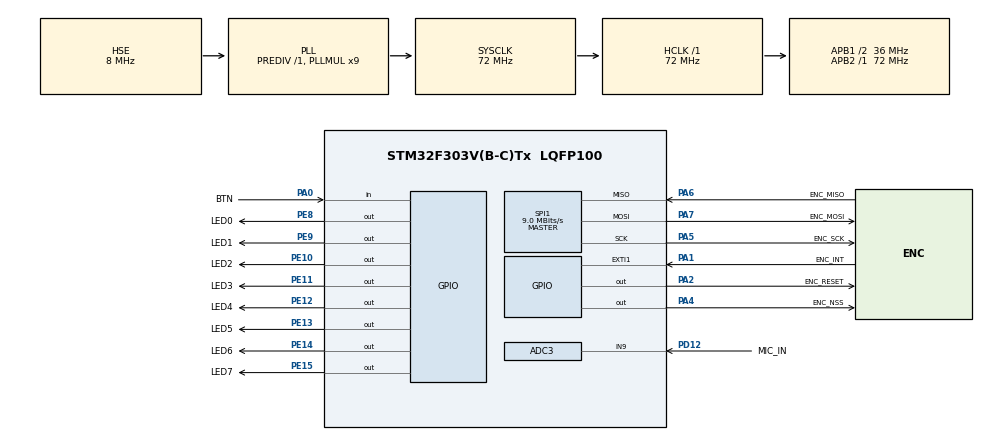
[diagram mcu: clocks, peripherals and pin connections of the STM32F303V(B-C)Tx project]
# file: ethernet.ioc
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ADC3.Channel-2\#ChannelRegularConversion=ADC_CHANNEL_9
ADC3.ClockPrescaler=ADC_CLOCK_SYNC_PCLK_DIV1
ADC3.DMAContinuousRequests=ENABLE
ADC3.ExternalTrigConv=ADC_EXTERNALTRIGCONV_T3_TRGO
ADC3.NbrOfConversionFlag=1
ADC3.Offset-2\#ChannelRegularConversion=0
ADC3.OffsetNumber-2\#ChannelRegularConversion=ADC_OFFSET_NONE
ADC3.Rank-2\#ChannelRegularConversion=1
ADC3.SamplingTime-2\#ChannelRegularConversion=ADC_SAMPLETIME_1CYCLE_5
ADC3.SamplingTimeOPAMP-2\#ChannelRegularConversion=ADC_SAMPLETIME_61CYCLES_5
ADC3.master=1
Dma.ADC3.2.Direction=DMA_PERIPH_TO_MEMORY
Dma.ADC3.2.Instance=DMA2_Channel5
Dma.ADC3.2.MemDataAlignment=DMA_MDATAALIGN_HALFWORD
Dma.ADC3.2.MemInc=DMA_MINC_ENABLE
Dma.ADC3.2.Mode=DMA_CIRCULAR
Dma.ADC3.2.PeriphDataAlignment=DMA_PDATAALIGN_HALFWORD
Dma.ADC3.2.PeriphInc=DMA_PINC_DISABLE
Dma.ADC3.2.Priority=DMA_PRIORITY_MEDIUM
Dma.Request0=SPI1_RX
Dma.Request1=SPI1_TX
Dma.Request2=ADC3
Dma.SPI1_RX.0.Direction=DMA_PERIPH_TO_MEMORY
Dma.SPI1_RX.0.Instance=DMA1_Channel2
Dma.SPI1_RX.0.MemDataAlignment=DMA_MDATAALIGN_BYTE
Dma.SPI1_RX.0.MemInc=DMA_MINC_ENABLE
Dma.SPI1_RX.0.Mode=DMA_NORMAL
Dma.SPI1_RX.0.PeriphDataAlignment=DMA_PDATAALIGN_BYTE
Dma.SPI1_RX.0.PeriphInc=DMA_PINC_DISABLE
Dma.SPI1_RX.0.Priority=DMA_PRIORITY_MEDIUM
Dma.SPI1_TX.1.Direction=DMA_MEMORY_TO_PERIPH
Dma.SPI1_TX.1.Instance=DMA1_Channel3
Dma.SPI1_TX.1.MemDataAlignment=DMA_MDATAALIGN_BYTE
Dma.SPI1_TX.1.MemInc=DMA_MINC_ENABLE
Dma.SPI1_TX.1.Mode=DMA_NORMAL
Dma.SPI1_TX.1.PeriphDataAlignment=DMA_PDATAALIGN_BYTE
Dma.SPI1_TX.1.PeriphInc=DMA_PINC_DISABLE
Dma.SPI1_TX.1.Priority=DMA_PRIORITY_MEDIUM
FREERTOS.HEAP_NUMBER=5
FREERTOS.INCLUDE_uxTaskPriorityGet=1
FREERTOS.INCLUDE_vTaskCleanUpResources=1
FREERTOS.INCLUDE_vTaskDelete=1
FREERTOS.INCLUDE_vTaskPrioritySet=1
FREERTOS.INCLUDE_xEventGroupSetBitFromISR=1
FREERTOS.INCLUDE_xTaskGetCurrentTaskHandle=1
FREERTOS.INCLUDE_xTaskGetHandle=1
FREERTOS.Tasks01=VCP2CLITask,24,128,vcp_task,Default,NULL,Dynamic,NULL,NULL
FREERTOS.configCHECK_FOR_STACK_OVERFLOW=0
FREERTOS.configGENERATE_RUN_TIME_STATS=1
FREERTOS.configTIMER_TASK_STACK_DEPTH=128
FREERTOS.configTOTAL_HEAP_SIZE=15360
FREERTOS.configUSE_IDLE_HOOK=1
FREERTOS.configUSE_MALLOC_FAILED_HOOK=1
FREERTOS.configUSE_NEWLIB_REENTRANT=1
FREERTOS.configUSE_STATS_FORMATTING_FUNCTIONS=1
Mcu.Family=STM32F3
Mcu.Name=STM32F303V(B-C)Tx
Mcu.Package=LQFP100
NVIC.DMA1_Channel2_IRQn=true\:5\:0\:false\:false\:true\:true\:false\:true
NVIC.DMA1_Channel3_IRQn=true\:5\:0\:false\:false\:true\:true\:false\:true
NVIC.DMA2_Channel5_IRQn=true\:5\:0\:false\:false\:true\:true\:false\:true
NVIC.EXTI1_IRQn=true\:5\:0\:false\:false\:true\:true\:true\:true
NVIC.PriorityGroup=NVIC_PRIORITYGROUP_4
NVIC.TIM2_IRQn=true\:15\:0\:false\:false\:true\:false\:false\:true
NVIC.TIM4_IRQn=true\:5\:0\:false\:false\:true\:true\:true\:true
NVIC.TimeBase=TIM2_IRQn
NVIC.TimeBaseIP=TIM2
PA0.GPIO_Label=BTN
PA0.Signal=GPIO_Input
PA1.GPIO_Label=ENC_INT
PA1.GPIO_ModeDefaultEXTI=GPIO_MODE_IT_FALLING
PA1.GPIO_PuPd=GPIO_NOPULL
PA1.Signal=GPXTI1
PA2.GPIO_Label=ENC_RESET
PA2.Signal=GPIO_Output
PA4.GPIO_Label=ENC_NSS
PA4.Signal=GPIO_Output
PA5.GPIO_Label=ENC_SCK
PA5.GPIO_PuPd=GPIO_PULLDOWN
PA5.Mode=Full_Duplex_Master
PA5.Signal=SPI1_SCK
PA6.GPIO_Label=ENC_MISO
PA6.Mode=Full_Duplex_Master
PA6.Signal=SPI1_MISO
PA7.GPIO_Label=ENC_MOSI
PA7.GPIO_PuPd=GPIO_PULLDOWN
PA7.Mode=Full_Duplex_Master
PA7.Signal=SPI1_MOSI
PD12.GPIO_Label=MIC_IN
PD12.Signal=ADCx_IN9P
PE10.GPIO_Label=LED2
PE10.Signal=GPIO_Output
PE11.GPIO_Label=LED3
PE11.Signal=GPIO_Output
PE12.GPIO_Label=LED4
PE12.Signal=GPIO_Output
PE13.GPIO_Label=LED5
PE13.Signal=GPIO_Output
PE14.GPIO_Label=LED6
PE14.Signal=GPIO_Output
PE15.GPIO_Label=LED7
PE15.Signal=GPIO_Output
PE8.GPIO_Label=LED0
PE8.Signal=GPIO_Output
PE9.GPIO_Label=LED1
PE9.Signal=GPIO_Output
PF0-OSC_IN.Mode=HSE-External-Oscillator
PF0-OSC_IN.Signal=RCC_OSC_IN
PF1-OSC_OUT.Mode=HSE-External-Oscillator
PF1-OSC_OUT.Signal=RCC_OSC_OUT
ProjectManager.HeapSize=0x0800
ProjectManager.StackSize=0x1000
ProjectManager.TargetToolchain=STM32CubeIDE
RCC.AHBFreq_Value=72000000
RCC.APB1CLKDivider=RCC_HCLK_DIV2
RCC.APB1Freq_Value=36000000
RCC.APB1TimFreq_Value=72000000
RCC.APB2Freq_Value=72000000
RCC.APB2TimFreq_Value=72000000
RCC.CortexFreq_Value=72000000
RCC.HCLKFreq_Value=72000000
RCC.HSE_VALUE=8000000
RCC.HSI_VALUE=8000000
RCC.LSE_VALUE=32768
RCC.PLLMUL=RCC_PLL_MUL9
RCC.PLLSourceVirtual=RCC_PLLSOURCE_HSE
RCC.PRESCALERUSB=RCC_USBCLKSOURCE_PLL_DIV1_5
RCC.SYSCLKFreq_VALUE=72000000
RCC.SYSCLKSourceVirtual=RCC_SYSCLKSOURCE_PLLCLK
RCC.USBFreq_Value=48000000
SH.ADCx_IN9P.0=ADC3_IN9,IN9-Single-Ended
SPI1.BaudRatePrescaler=SPI_BAUDRATEPRESCALER_8
SPI1.CLKPhase=SPI_PHASE_1EDGE
SPI1.CalculateBaudRate=9.0 MBits/s
SPI1.DataSize=SPI_DATASIZE_8BIT
SPI1.Direction=SPI_DIRECTION_2LINES
SPI1.Mode=SPI_MODE_MASTER
SPI1.TIMode=SPI_TIMODE_DISABLE
SPI1.VirtualType=VM_MASTER
STMicroelectronics.X-CUBE-ALGOBUILD.1.2.1.LibraryCcDSPOoLibraryJjDSPOoLibrary=true
TIM1.AutoReloadPreload=TIM_AUTORELOAD_PRELOAD_ENABLE
TIM1.Period=8999
TIM1.Prescaler=7
TIM3.AutoReloadPreload=TIM_AUTORELOAD_PRELOAD_ENABLE
TIM3.Period=1499
TIM3.TIM_MasterOutputTrigger=TIM_TRGO_UPDATE
TIM4.AutoReloadPreload=TIM_AUTORELOAD_PRELOAD_ENABLE
TIM4.Period=719
TIM4.TIM_MasterOutputTrigger=TIM_TRGO_RESET
VP_FREERTOS_VS_CMSIS_V2.Mode=CMSIS_V2
VP_STMicroelectronics.X-CUBE-ALGOBUILD_VS_DSPOoLibraryJjLibrary_1.2.1_1.2.1.Mode=DSPOoLibraryJjLibrary
VP_SYS_VS_tim2.Mode=TIM2
VP_TIM1_VS_ClockSourceINT.Mode=Internal
VP_TIM3_VS_ClockSourceINT.Mode=Internal
VP_TIM4_VS_ClockSourceINT.Mode=Internal
board=custom

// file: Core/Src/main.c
/* USER CODE BEGIN Header */
/**
  ******************************************************************************
  * @file           : main.c
  * @brief          : Main program body
  ******************************************************************************
  * @attention
  *
  * Copyright (c) 2021 STMicroelectronics.
  * All rights reserved.
  *
  * This software is licensed under terms that can be found in the LICENSE file
  * in the root directory of this software component.
  * If no LICENSE file comes with this software, it is provided AS-IS.
  *
  ******************************************************************************
  */
/* USER CODE END Header */
#include "main.h"
#include "cmsis_os.h"

/* USER CODE BEGIN Includes */
//#include "usbd_cdc_if.h"
/* USER CODE END Includes */

ADC_HandleTypeDef hadc3;
DMA_HandleTypeDef hdma_adc3;

SPI_HandleTypeDef hspi1;
DMA_HandleTypeDef hdma_spi1_rx;
DMA_HandleTypeDef hdma_spi1_tx;

TIM_HandleTypeDef htim1;
TIM_HandleTypeDef htim3;
TIM_HandleTypeDef htim4;

/* Definitions for VCP2CLITask */
osThreadId_t VCP2CLITaskHandle;
const osThreadAttr_t VCP2CLITask_attributes = {
  .name = "VCP2CLITask",
  .stack_size = 128 * 4,
  .priority = (osPriority_t) osPriorityNormal,
};

void SystemClock_Config(void);
static void MX_GPIO_Init(void);
static void MX_SPI1_Init(void);
static void MX_TIM1_Init(void);
static void MX_DMA_Init(void);
static void MX_TIM4_Init(void);
static void MX_ADC3_Init(void);
static void MX_TIM3_Init(void);
void vcp_task(void *argument);

/* USER CODE BEGIN 0 */
unsigned long taskruntime = 0;

void configureTimerForRunTimeStats(void){
	HAL_TIM_Base_Start_IT(&htim4);
}
unsigned long getRunTimeCounterValue(void){
	return taskruntime;
}

/* USER CODE END 0 */

int main(void)
{

  /* MCU Configuration--------------------------------------------------------*/

  /* Reset of all peripherals, Initializes the Flash interface and the Systick. */
  HAL_Init();

  /* Configure the system clock */
  SystemClock_Config();

  /* Initialize all configured peripherals */
  MX_GPIO_Init();
  MX_SPI1_Init();
  MX_TIM1_Init();
  MX_DMA_Init();
  MX_TIM4_Init();
  MX_ADC3_Init();
  MX_TIM3_Init();

  /* Init scheduler */
  osKernelInitialize();

  /* Create the thread(s) */
  /* creation of VCP2CLITask */
//  VCP2CLITaskHandle = osThreadNew(vcp_task, NULL, &VCP2CLITask_attributes);

  /* USER CODE BEGIN RTOS_THREADS */
  /* add threads, ... */
  adc_fft_start();
  FreeRTOS_ENC28J60Init();

  /* USER CODE END RTOS_THREADS */

  /* Start scheduler */
  osKernelStart();

  /* We should never get here as control is now taken by the scheduler */
  /* Infinite loop */
  while (1)
  {

  }
}

void SystemClock_Config(void)
{
  RCC_OscInitTypeDef RCC_OscInitStruct = {0};
  RCC_ClkInitTypeDef RCC_ClkInitStruct = {0};
  RCC_PeriphCLKInitTypeDef PeriphClkInit = {0};

  /** Initializes the RCC Oscillators according to the specified parameters
  * in the RCC_OscInitTypeDef structure.
  */
  RCC_OscInitStruct.OscillatorType = RCC_OSCILLATORTYPE_HSE;
  RCC_OscInitStruct.HSEState = RCC_HSE_ON;
  RCC_OscInitStruct.HSEPredivValue = RCC_HSE_PREDIV_DIV1;
  RCC_OscInitStruct.HSIState = RCC_HSI_ON;
  RCC_OscInitStruct.PLL.PLLState = RCC_PLL_ON;
  RCC_OscInitStruct.PLL.PLLSource = RCC_PLLSOURCE_HSE;
  RCC_OscInitStruct.PLL.PLLMUL = RCC_PLL_MUL9;
  if (HAL_RCC_OscConfig(&RCC_OscInitStruct) != HAL_OK)
  {
    Error_Handler();
  }
  /** Initializes the CPU, AHB and APB buses clocks
  */
  RCC_ClkInitStruct.ClockType = RCC_CLOCKTYPE_HCLK|RCC_CLOCKTYPE_SYSCLK
                              |RCC_CLOCKTYPE_PCLK1|RCC_CLOCKTYPE_PCLK2;
  RCC_ClkInitStruct.SYSCLKSource = RCC_SYSCLKSOURCE_PLLCLK;
  RCC_ClkInitStruct.AHBCLKDivider = RCC_SYSCLK_DIV1;
  RCC_ClkInitStruct.APB1CLKDivider = RCC_HCLK_DIV2;
  RCC_ClkInitStruct.APB2CLKDivider = RCC_HCLK_DIV1;

  if (HAL_RCC_ClockConfig(&RCC_ClkInitStruct, FLASH_LATENCY_2) != HAL_OK)
  {
    Error_Handler();
  }
  PeriphClkInit.PeriphClockSelection = RCC_PERIPHCLK_TIM1;
  PeriphClkInit.Tim1ClockSelection = RCC_TIM1CLK_HCLK;
  if (HAL_RCCEx_PeriphCLKConfig(&PeriphClkInit) != HAL_OK)
  {
    Error_Handler();
  }
}

static void MX_ADC3_Init(void)
{

  ADC_MultiModeTypeDef multimode = {0};
  ADC_ChannelConfTypeDef sConfig = {0};

  /** Common config
  */
  hadc3.Instance = ADC3;
  hadc3.Init.ClockPrescaler = ADC_CLOCK_SYNC_PCLK_DIV1;
  hadc3.Init.Resolution = ADC_RESOLUTION_12B;
  hadc3.Init.ScanConvMode = ADC_SCAN_DISABLE;
  hadc3.Init.ContinuousConvMode = DISABLE;
  hadc3.Init.DiscontinuousConvMode = DISABLE;
  hadc3.Init.ExternalTrigConvEdge = ADC_EXTERNALTRIGCONVEDGE_RISING;
  hadc3.Init.ExternalTrigConv = ADC_EXTERNALTRIGCONV_T3_TRGO;
  hadc3.Init.DataAlign = ADC_DATAALIGN_RIGHT;
  hadc3.Init.NbrOfConversion = 1;
  hadc3.Init.DMAContinuousRequests = ENABLE;
  hadc3.Init.EOCSelection = ADC_EOC_SINGLE_CONV;
  hadc3.Init.LowPowerAutoWait = DISABLE;
  hadc3.Init.Overrun = ADC_OVR_DATA_OVERWRITTEN;
  if (HAL_ADC_Init(&hadc3) != HAL_OK)
  {
    Error_Handler();
  }
  /** Configure the ADC multi-mode
  */
  multimode.Mode = ADC_MODE_INDEPENDENT;
  if (HAL_ADCEx_MultiModeConfigChannel(&hadc3, &multimode) != HAL_OK)
  {
    Error_Handler();
  }
  /** Configure Regular Channel
  */
  sConfig.Channel = ADC_CHANNEL_9;
  sConfig.Rank = ADC_REGULAR_RANK_1;
  sConfig.SingleDiff = ADC_SINGLE_ENDED;
  sConfig.SamplingTime = ADC_SAMPLETIME_1CYCLE_5;
  sConfig.OffsetNumber = ADC_OFFSET_NONE;
  sConfig.Offset = 0;
  if (HAL_ADC_ConfigChannel(&hadc3, &sConfig) != HAL_OK)
  {
    Error_Handler();
  }

}

static void MX_SPI1_Init(void)
{

  /* SPI1 parameter configuration*/
  hspi1.Instance = SPI1;
  hspi1.Init.Mode = SPI_MODE_MASTER;
  hspi1.Init.Direction = SPI_DIRECTION_2LINES;
  hspi1.Init.DataSize = SPI_DATASIZE_8BIT;
  hspi1.Init.CLKPolarity = SPI_POLARITY_LOW;
  hspi1.Init.CLKPhase = SPI_PHASE_1EDGE;
  hspi1.Init.NSS = SPI_NSS_SOFT;
  hspi1.Init.BaudRatePrescaler = SPI_BAUDRATEPRESCALER_8;
  hspi1.Init.FirstBit = SPI_FIRSTBIT_MSB;
  hspi1.Init.TIMode = SPI_TIMODE_DISABLE;
  hspi1.Init.CRCCalculation = SPI_CRCCALCULATION_DISABLE;
  hspi1.Init.CRCPolynomial = 7;
  hspi1.Init.CRCLength = SPI_CRC_LENGTH_DATASIZE;
  hspi1.Init.NSSPMode = SPI_NSS_PULSE_ENABLE;
  if (HAL_SPI_Init(&hspi1) != HAL_OK)
  {
    Error_Handler();
  }

}

static void MX_TIM1_Init(void)
{

  TIM_ClockConfigTypeDef sClockSourceConfig = {0};
  TIM_MasterConfigTypeDef sMasterConfig = {0};

  htim1.Instance = TIM1;
  htim1.Init.Prescaler = 7;
  htim1.Init.CounterMode = TIM_COUNTERMODE_UP;
  htim1.Init.Period = 8999;
  htim1.Init.ClockDivision = TIM_CLOCKDIVISION_DIV1;
  htim1.Init.RepetitionCounter = 0;
  htim1.Init.AutoReloadPreload = TIM_AUTORELOAD_PRELOAD_ENABLE;
  if (HAL_TIM_Base_Init(&htim1) != HAL_OK)
  {
    Error_Handler();
  }
  sClockSourceConfig.ClockSource = TIM_CLOCKSOURCE_INTERNAL;
  if (HAL_TIM_ConfigClockSource(&htim1, &sClockSourceConfig) != HAL_OK)
  {
    Error_Handler();
  }
  sMasterConfig.MasterOutputTrigger = TIM_TRGO_RESET;
  sMasterConfig.MasterOutputTrigger2 = TIM_TRGO2_RESET;
  sMasterConfig.MasterSlaveMode = TIM_MASTERSLAVEMODE_DISABLE;
  if (HAL_TIMEx_MasterConfigSynchronization(&htim1, &sMasterConfig) != HAL_OK)
  {
    Error_Handler();
  }

}

static void MX_TIM3_Init(void)
{

  TIM_ClockConfigTypeDef sClockSourceConfig = {0};
  TIM_MasterConfigTypeDef sMasterConfig = {0};

  htim3.Instance = TIM3;
  htim3.Init.Prescaler = 0;
  htim3.Init.CounterMode = TIM_COUNTERMODE_UP;
  htim3.Init.Period = 1499;
  htim3.Init.ClockDivision = TIM_CLOCKDIVISION_DIV1;
  htim3.Init.AutoReloadPreload = TIM_AUTORELOAD_PRELOAD_ENABLE;
  if (HAL_TIM_Base_Init(&htim3) != HAL_OK)
  {
    Error_Handler();
  }
  sClockSourceConfig.ClockSource = TIM_CLOCKSOURCE_INTERNAL;
  if (HAL_TIM_ConfigClockSource(&htim3, &sClockSourceConfig) != HAL_OK)
  {
    Error_Handler();
  }
  sMasterConfig.MasterOutputTrigger = TIM_TRGO_UPDATE;
  sMasterConfig.MasterSlaveMode = TIM_MASTERSLAVEMODE_DISABLE;
  if (HAL_TIMEx_MasterConfigSynchronization(&htim3, &sMasterConfig) != HAL_OK)
  {
    Error_Handler();
  }

}

static void MX_TIM4_Init(void)
{

  TIM_ClockConfigTypeDef sClockSourceConfig = {0};
  TIM_MasterConfigTypeDef sMasterConfig = {0};

  htim4.Instance = TIM4;
  htim4.Init.Prescaler = 0;
  htim4.Init.CounterMode = TIM_COUNTERMODE_UP;
  htim4.Init.Period = 719;
  htim4.Init.ClockDivision = TIM_CLOCKDIVISION_DIV1;
  htim4.Init.AutoReloadPreload = TIM_AUTORELOAD_PRELOAD_ENABLE;
  if (HAL_TIM_Base_Init(&htim4) != HAL_OK)
  {
    Error_Handler();
  }
  sClockSourceConfig.ClockSource = TIM_CLOCKSOURCE_INTERNAL;
  if (HAL_TIM_ConfigClockSource(&htim4, &sClockSourceConfig) != HAL_OK)
  {
    Error_Handler();
  }
  sMasterConfig.MasterOutputTrigger = TIM_TRGO_RESET;
  sMasterConfig.MasterSlaveMode = TIM_MASTERSLAVEMODE_DISABLE;
  if (HAL_TIMEx_MasterConfigSynchronization(&htim4, &sMasterConfig) != HAL_OK)
  {
    Error_Handler();
  }

}

static void MX_DMA_Init(void)
{

  /* DMA controller clock enable */
  __HAL_RCC_DMA1_CLK_ENABLE();
  __HAL_RCC_DMA2_CLK_ENABLE();

  /* DMA interrupt init */
  /* DMA1_Channel2_IRQn interrupt configuration */
  HAL_NVIC_SetPriority(DMA1_Channel2_IRQn, 5, 0);
  HAL_NVIC_EnableIRQ(DMA1_Channel2_IRQn);
  /* DMA1_Channel3_IRQn interrupt configuration */
  HAL_NVIC_SetPriority(DMA1_Channel3_IRQn, 5, 0);
  HAL_NVIC_EnableIRQ(DMA1_Channel3_IRQn);
  /* DMA2_Channel5_IRQn interrupt configuration */
  HAL_NVIC_SetPriority(DMA2_Channel5_IRQn, 5, 0);
  HAL_NVIC_EnableIRQ(DMA2_Channel5_IRQn);

}

static void MX_GPIO_Init(void)
{
  GPIO_InitTypeDef GPIO_InitStruct = {0};

  /* GPIO Ports Clock Enable */
  __HAL_RCC_GPIOF_CLK_ENABLE();
  __HAL_RCC_GPIOA_CLK_ENABLE();
  __HAL_RCC_GPIOE_CLK_ENABLE();
  __HAL_RCC_GPIOD_CLK_ENABLE();

  /*Configure GPIO pin Output Level */
  HAL_GPIO_WritePin(GPIOA, ENC_RESET_Pin|ENC_NSS_Pin, GPIO_PIN_RESET);

  /*Configure GPIO pin Output Level */
  HAL_GPIO_WritePin(GPIOE, LED0_Pin|LED1_Pin|LED2_Pin|LED3_Pin
                          |LED4_Pin|LED5_Pin|LED6_Pin|LED7_Pin, GPIO_PIN_RESET);

  /*Configure GPIO pin : BTN_Pin */
  GPIO_InitStruct.Pin = BTN_Pin;
  GPIO_InitStruct.Mode = GPIO_MODE_INPUT;
  GPIO_InitStruct.Pull = GPIO_NOPULL;
  HAL_GPIO_Init(BTN_GPIO_Port, &GPIO_InitStruct);

  /*Configure GPIO pin : ENC_INT_Pin */
  GPIO_InitStruct.Pin = ENC_INT_Pin;
  GPIO_InitStruct.Mode = GPIO_MODE_IT_FALLING;
  GPIO_InitStruct.Pull = GPIO_NOPULL;
  HAL_GPIO_Init(ENC_INT_GPIO_Port, &GPIO_InitStruct);

  /*Configure GPIO pins : ENC_RESET_Pin ENC_NSS_Pin */
  GPIO_InitStruct.Pin = ENC_RESET_Pin|ENC_NSS_Pin;
  GPIO_InitStruct.Mode = GPIO_MODE_OUTPUT_PP;
  GPIO_InitStruct.Pull = GPIO_NOPULL;
  GPIO_InitStruct.Speed = GPIO_SPEED_FREQ_LOW;
  HAL_GPIO_Init(GPIOA, &GPIO_InitStruct);

  /*Configure GPIO pins : LED0_Pin LED1_Pin LED2_Pin LED3_Pin
                           LED4_Pin LED5_Pin LED6_Pin LED7_Pin */
  GPIO_InitStruct.Pin = LED0_Pin|LED1_Pin|LED2_Pin|LED3_Pin
                          |LED4_Pin|LED5_Pin|LED6_Pin|LED7_Pin;
  GPIO_InitStruct.Mode = GPIO_MODE_OUTPUT_PP;
  GPIO_InitStruct.Pull = GPIO_NOPULL;
  GPIO_InitStruct.Speed = GPIO_SPEED_FREQ_LOW;
  HAL_GPIO_Init(GPIOE, &GPIO_InitStruct);

  /* EXTI interrupt init*/
  HAL_NVIC_SetPriority(EXTI1_IRQn, 5, 0);
  HAL_NVIC_EnableIRQ(EXTI1_IRQn);

}

/* USER CODE BEGIN 4 */
//uint8_t usb_rx_flag = 0;
//extern uint8_t UserRxBufferFS[APP_RX_DATA_SIZE];
//extern uint8_t UserTxBufferFS[APP_TX_DATA_SIZE];
//char usb_rx_buffer[1400] = {0};
//char usb_tx_buffer[1400] = {0};

//uint16_t len = 0;
/* USER CODE END 4 */

void vcp_task(void *argument)
{
  /* USER CODE BEGIN 5 */
  /* Infinite loop */
  for(;;){

	 // ulTaskNotifyTake(pdFALSE, portMAX_DELAY);
	  /*
	  while(CDC_Transmit_FS(UserRxBufferFS, strlen(UserRxBufferFS) != USBD_OK)){};

	  if(UserRxBufferFS[0] != '\r'){
		  //while(CDC_Transmit_FS(UserRxBufferFS, strlen(UserRxBufferFS) != USBD_OK)){};

		  //UserRxBufferFS[strlen(UserRxBufferFS)] = 0x00;
		  strncpy(usb_rx_buffer + strlen(usb_rx_buffer), UserRxBufferFS, 2);
	  }else{
		  //while(CDC_Transmit_FS("\r\n", sizeof("\r\n") != USBD_OK)){}

		  UserTxBufferFS[0] = 0;

		  FreeRTOS_CLIProcessCommand(usb_rx_buffer, UserTxBufferFS, APP_TX_DATA_SIZE);

		  usb_rx_buffer[0] = 0;
		  while(CDC_Transmit_FS(UserTxBufferFS, strlen(UserTxBufferFS)) != USBD_OK){};
	  }
	  */
  }
  /* USER CODE END 5 */
}

void HAL_TIM_PeriodElapsedCallback(TIM_HandleTypeDef *htim)
{
  if (htim->Instance == TIM2) {
    HAL_IncTick();
  }
  /* USER CODE BEGIN Callback 1 */
  else if(htim->Instance == TIM4){
	  taskruntime++;
  }
  /* USER CODE END Callback 1 */
}

void Error_Handler(void)
{
  /* USER CODE BEGIN Error_Handler_Debug */
  /* User can add his own implementation to report the HAL error return state */
  __disable_irq();
  HAL_GPIO_TogglePin(LED3_GPIO_Port, LED3_Pin);
  while (1)
  {
  }
  /* USER CODE END Error_Handler_Debug */
}

#ifdef  USE_FULL_ASSERT
/**
  * @brief  Reports the name of the source file and the source line number
  *         where the assert_param error has occurred.
  * @param  file: pointer to the source file name
  * @param  line: assert_param error line source number
  * @retval None
  */
void assert_failed(uint8_t *file, uint32_t line)
{
  /* USER CODE BEGIN 6 */
	HAL_GPIO_TogglePin(LED2_GPIO_Port, LED2_Pin);
  /* User can add his own implementation to report the file name and line number,
     ex: printf("Wrong parameters value: file %s on line %d\r\n", file, line) */
  /* USER CODE END 6 */
}
#endif /* USE_FULL_ASSERT */

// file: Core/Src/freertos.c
/* USER CODE BEGIN Header */
/**
  ******************************************************************************
  * File Name          : freertos.c
  * Description        : Code for freertos applications
  ******************************************************************************
  * @attention
  *
  * Copyright (c) 2021 STMicroelectronics.
  * All rights reserved.
  *
  * This software is licensed under terms that can be found in the LICENSE file
  * in the root directory of this software component.
  * If no LICENSE file comes with this software, it is provided AS-IS.
  *
  ******************************************************************************
  */
/* USER CODE END Header */

#include "FreeRTOS.h"
#include "task.h"
#include "main.h"

/* Hook prototypes */
void configureTimerForRunTimeStats(void);
unsigned long getRunTimeCounterValue(void);
void vApplicationIdleHook(void);
void vApplicationMallocFailedHook(void);

/* USER CODE BEGIN 1 */
/* Functions needed when configGENERATE_RUN_TIME_STATS is on */
__weak void configureTimerForRunTimeStats(void)
{

}

__weak unsigned long getRunTimeCounterValue(void)
{
return 0;
}
/* USER CODE END 1 */

/* USER CODE BEGIN 2 */
void vApplicationIdleHook( void )
{
   /* vApplicationIdleHook() will only be called if configUSE_IDLE_HOOK is set
   to 1 in FreeRTOSConfig.h. It will be called on each iteration of the idle
   task. It is essential that code added to this hook function never attempts
   to block in any way (for example, call xQueueReceive() with a block time
   specified, or call vTaskDelay()). If the application makes use of the
   vTaskDelete() API function (as this demo application does) then it is also
   important that vApplicationIdleHook() is permitted to return to its calling
   function, because it is the responsibility of the idle task to clean up
   memory allocated by the kernel to any task that has since been deleted. */
}
/* USER CODE END 2 */

/* USER CODE BEGIN 5 */
void vApplicationMallocFailedHook(void)
{
   /* vApplicationMallocFailedHook() will only be called if
   configUSE_MALLOC_FAILED_HOOK is set to 1 in FreeRTOSConfig.h. It is a hook
   function that will get called if a call to pvPortMalloc() fails.
   pvPortMalloc() is called internally by the kernel whenever a task, queue,
   timer or semaphore is created. It is also called by various parts of the
   demo application. If heap_1.c or heap_2.c are used, then the size of the
   heap available to pvPortMalloc() is defined by configTOTAL_HEAP_SIZE in
   FreeRTOSConfig.h, and the xPortGetFreeHeapSize() API function can be used
   to query the size of free heap space that remains (although it does not
   provide information on how the remaining heap might be fragmented). */
}
/* USER CODE END 5 */
